# earlgrey register map
Vendor: lowRISC; File version: 0.1
CPU: ibex rev01, little endian, no MPU, no FPU, VTOR, 2 interrupt priority bits, 2 interrupts
Registers are 32-bit, read-write, no defined reset value unless marked. A register's access mark holds for its fields unless they carry their own. Offsets are from the block's base; [hi:lo] are bit positions; {n}, {i} and the like mark numbered series; 'fields as' and 'values as' point back to an identical list.

## ADC_CTRL_AON — Low-power controller for a dual-channel ADC with filtering and debouncing capability
Base 0x40440000
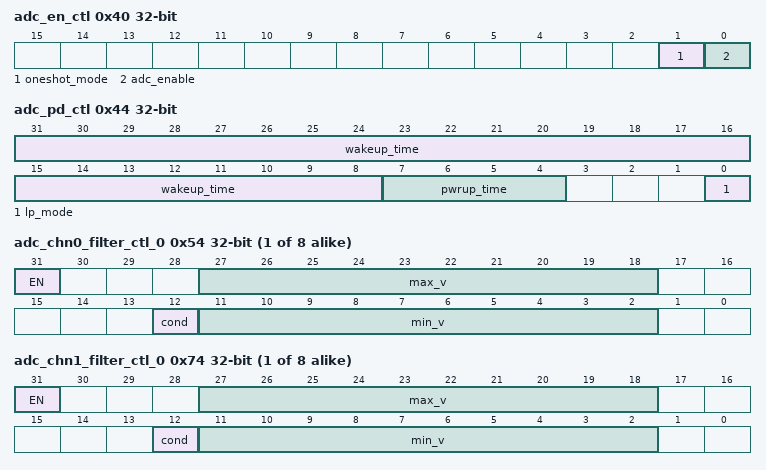
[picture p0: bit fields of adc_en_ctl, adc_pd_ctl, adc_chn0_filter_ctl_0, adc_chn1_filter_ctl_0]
0x40 adc_en_ctl — ADC enable control register
  [1] oneshot_mode — Oneshot mode does not care about the filter value. 1'b0: disable; 1'b1: enable
  [0] adc_enable — 1'b0: to power down ADC and ADC_CTRL FSM will enter the reset state; 1'b1: to power up ADC and ADC_CTRL FSM will start
0x44 adc_pd_ctl — ADC PowerDown(PD) control register
  [31:8] wakeup_time — How often FSM wakes up from ADC PD mode to take a sample, measured in always on clock cycles.
  [7:4] pwrup_time — ADC power up time, measured in always on clock cycles.After power up time is reached, the ADC controller needs one additional cycle before an ADC channel is selected for access.
  [0] lp_mode — 1'b0: adc_pd is disabled, use adc_sample_ctl. 1'b1: adc_pd is enabled, use both adc_lp_sample_ctl & adc_sample_ctl
0x48 adc_lp_sample_ctl — ADC Low-Power(LP) sample control register
  [7:0] lp_sample_cnt — The number of samples in low-power mode when the low-power mode is enabled.After the programmed number is met, ADC won't be powered down any more.This value must be 1 or larger.
0x4C adc_sample_ctl — ADC sample control register
  [15:0] np_sample_cnt — The number of samples in normal-power mode to meet the debounce spec.Used after the low-power mode condition is met or in the normal power mode.This value must be 1 or larger.
0x50 adc_fsm_rst — ADC FSM reset control
  [0] rst_en — 1'b0: Normal functional mode. 1'b1: SW to reset all the FSMs and timers
{0x54+4i} adc_chn0_filter_ctl_{i} (i=0..7) — ADC channel0 filter rangeUp to 8 filters can be configured per channel and each filter has an associated [min, max] range.The condition bit then defines whether the sample values of that channel need to lie within the range or outside to create a match.The filter range bounds can be configured with a granularity of 2.148mV.
  [31] EN — Enable for filter
  [27:18] max_v — 10-bit for chn0 filter max value
  [12] cond — 1-bit for the condition; 1'b0 means min<=ADC<=max, 1'b1 means ADC>max or ADC<min
  [11:2] min_v — 10-bit for chn0 filter min value
{0x74+4i} adc_chn1_filter_ctl_{i} (i=0..7) — ADC channel1 filter rangeUp to 8 filters can be configured per channel and each filter has an associated [min, max] range.The condition bit then defines whether the sample values of that channel need to lie within the range or outside to create a match.The filter range bounds can be configured with a granularity of 2.148mV.
  fields as adc_chn0_filter_ctl_0
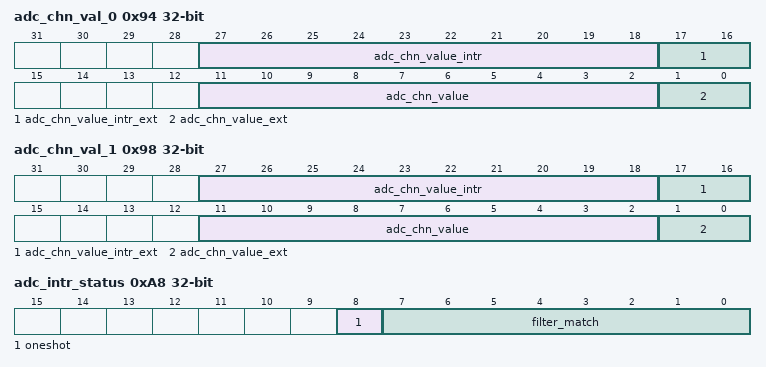
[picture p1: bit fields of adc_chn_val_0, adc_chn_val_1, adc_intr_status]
0x94 adc_chn_val_0 ro — ADC value sampled on channel
  [27:18] adc_chn_value_intr — ADC value sampled on channel when the interrupt is raised(debug cable is attached or disconnected), each step is 2.148mV
  [17:16] adc_chn_value_intr_ext — 2-bit extension; RO 0
  [11:2] adc_chn_value — Latest ADC value sampled on channel. each step is 2.148mV
  [1:0] adc_chn_value_ext — 2-bit extension; RO 0
0x98 adc_chn_val_1 ro — ADC value sampled on channel
  fields as adc_chn_val_0
0x9C adc_wakeup_ctl — Enable filter matches as wakeups
  [7:0] EN — 0: filter match wil not generate wakeupe; 1: filter match will generate wakeup
0xA0 filter_status — Adc filter match statusIndicates whether a particular filter has matched on all channels.
  [7:0] COND — 0: filter condition is not met; 1: filter condition is met
0xA4 adc_intr_ctl — Interrupt enable controls.adc_ctrl sends out only 1 interrupt, so this register controlswhich internal sources are actually registered.This register uses the same bit enumeration as !!ADC_INTR_STATUS
  [8:0] EN — 0: interrupt source is not enabled; 1: interrupt source is enabled
0xA8 adc_intr_status — Debug cable internal status
  [8] oneshot — 0: oneshot sample is not done ; 1: oneshot sample is done
  [7:0] filter_match — 0: filter condition is not met; 1: filter condition is met
